# PMUD register map
Vendor: Texas Instruments
Peripheral module from a debugger description file (folder CC23x0R2).
Registers are 32-bit, access per field, reset 0x0 unless marked. A register's access mark holds for its fields unless they carry their own. Offsets are as the file gives them; lines under a group give offsets from that group; [hi:lo] are bit positions; {n}, {i} and the like mark numbered series; 'fields as' and 'values as' point back to an identical list; <NAME> marks a mode.

## PMUD — Digital control signals for VDDR regulator and Battery Monitor
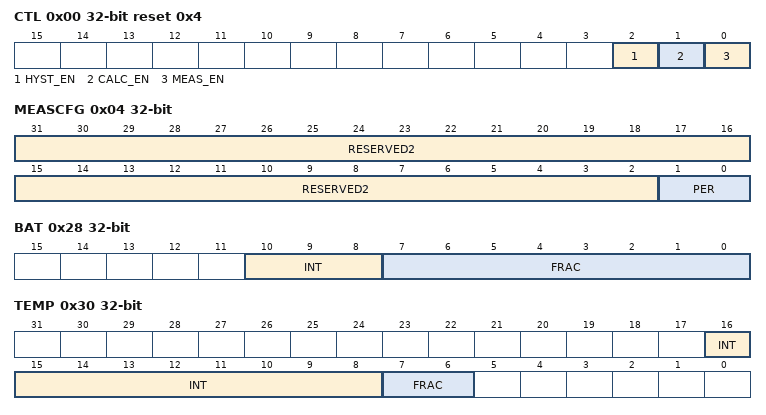
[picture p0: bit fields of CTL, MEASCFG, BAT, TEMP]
0x00 CTL reset 0x4 — Control General Configuration of BATMON
  [2] HYST_EN rw — Enables hysteresis on both battery and temperature measurements.
    1=EN (Enable); 0=DIS (Disable)
  [1] CALC_EN rw — Configuration of the calculation block that converts the digital battery/temperature level to a Volt/Celsius value.
    1=EN (Calculation enabled); 0=DIS (Calculation disabled)
  [0] MEAS_EN rw — Configuration of the measurement block that interfaces with the analog domain.
    1=EN (Measurements enabled (battery voltage and temperature)); 0=DIS (Measurements disabled)
0x04 MEASCFG — Internal. Only to be used through TI provided API.
  [31:2] RESERVED2 ro — Internal. Only to be used through TI provided API.
  [1:0] PER rw — Internal. Only to be used through TI provided API.
    3=_32CYC (Internal. Only to be used through TI provided API.); 2=_16CYC (Internal. Only to be used through TI provided API.); 1=_8CYC (Internal. Only to be used through TI provided API.); 0=CONT (Internal. Only to be used through TI provided API.)
0x28 BAT ro — Last Measured Battery Voltage This register should be read when BATUPD.STA = 1
  [10:8] INT — Integer part: 0x0: Battery voltage = 0V + fractional part ... 0x3: Battery voltage = 3V + fractional part 0x4: Battery voltage = 4V + fractional part
  [7:0] FRAC — Fractional part, standard binary fractional encoding. 0x00: .0V ... 0x20: 1/8 = .125V 0x40: 1/4 = .25V 0x80: 1/2 = .5V ... 0xA0: 1/2 + 1/8 = .625V ... 0xFF: 1/2 + 1/4 + 1/8 + ... + 1/256 = 0.99V
0x2C BATUPD — Battery Update Indicates BAT Updates
  [0] STA rw — Battery update status. Write 1 to clear the status.
    1=UPD (New battery voltage present); 0=NOUPD (No update since last clear)
0x30 TEMP ro — Last measured Temperature in Degree Celsius This register should be read when TEMPUPD.STA = 1.
  [16:8] INT — Integer part of temperature value (signed) Total value = INT + FRAC 2's complement encoding 0x100: Min value (-256°C) 0x1D8: -40°C 0x1FF: -1°C 0x00: 0°C 0x1B: 27°C 0x55: 85°C 0xFF: Max value (255°C)
  [7:6] FRAC — Fractional part of temperature value. Total value = INT + FRAC The encoding is an extension of the 2's complement encoding. 00: 0.0°C 01: 0.25°C 10: 0.5°C 11: 0.75°C For example: 000000001,00 = ( 1+0,00) = 1,00 000000000,11 = ( 0+0,75) = 0,75 000000000,10 = ( 0+0,50) = 0,50 000000000,01 = ( 0+0,25) = 0,25 000000000,00 = ( 0+0,00) = 0,00 111111111,11 = (-1+0,75) = -0,25 111111111,10 = (-1+0,50) = -0,50 111111111,01 = (-1+0,25) = -0,75 111111111,00 = (-1+0,00) = -1,00 111111110,11 = (-2+0,75) = -1,25
0x34 TEMPUPD — Temperature Update Indicates TEMP Updates
  [0] STA rw — Temperature update status. Write 1 to clear the status.
    1=UPD (New temperature value present); 0=NOUPD (No temperature update since last clear)
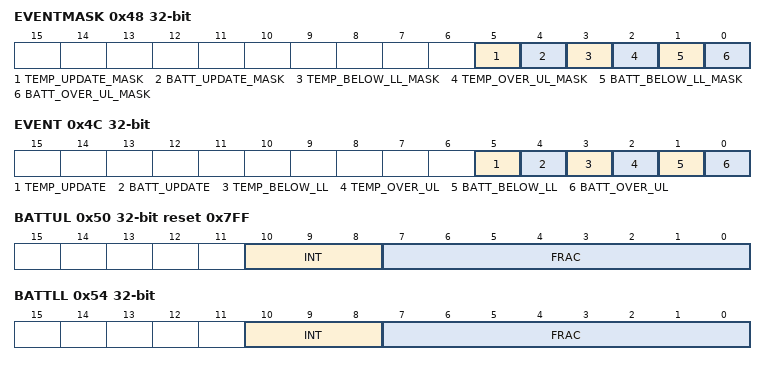
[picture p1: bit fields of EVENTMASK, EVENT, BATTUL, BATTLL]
0x48 EVENTMASK
  [5] TEMP_UPDATE_MASK rw — 1: EVENT.TEMP_UPDATE contributes to combined event from BATMON 0: EVENT.TEMP_UPDATE does not contribute to combined event from BATMON
  [4] BATT_UPDATE_MASK rw — 1: EVENT.BATT_UPDATE contributes to combined event from BATMON 0: EVENT.BATT_UPDATE does not contribute to combined event from BATMON
  [3] TEMP_BELOW_LL_MASK rw — 1: EVENT.TEMP_BELOW_LL contributes to combined event from BATMON 0: EVENT.TEMP_BELOW_LL does not contribute to combined event from BATMON
  [2] TEMP_OVER_UL_MASK rw — 1: EVENT.TEMP_OVER_UL contributes to combined event from BATMON 0: EVENT.TEMP_OVER_UL does not contribute to combined event from BATMON
  [1] BATT_BELOW_LL_MASK rw — 1: EVENT.BATT_BELOW_LL contributes to combined event from BATMON 0: EVENT.BATT_BELOW_LL does not contribute to combined event from BATMON
  [0] BATT_OVER_UL_MASK rw — 1: EVENT.BATT_OVER_UL contributes to combined event from BATMON 0: EVENT.BATT_OVER_UL does not contribute to combined event from BATMON
0x4C EVENT
  [5] TEMP_UPDATE rw — Alias to TEMPUPD.STA
  [4] BATT_UPDATE rw — Alias to BATUPD.STA
  [3] TEMP_BELOW_LL rw — Read: 1: Temperature level is below the lower limit set by TEMPLL. 0: Temperature level is not below the lower limit set by TEMPLL. Write: 1: Clears the flag 0: No change in the flag
  [2] TEMP_OVER_UL rw — Read: 1: Temperature level is above the upper limit set by TEMPUL. 0: Temperature level is not above the upper limit set by TEMPUL. Write: 1: Clears the flag 0: No change in the flag
  [1] BATT_BELOW_LL rw — Read: 1: Battery level is below the lower limit set by BATTLL. 0: Battery level is not below the lower limit set by BATTLL. Write: 1: Clears the flag 0: No change in the flag
  [0] BATT_OVER_UL rw — Read: 1: Battery level is above the upper limit set by BATTUL. 0: Battery level is not above the upper limit set by BATTUL. Write: 1: Clears the flag 0: No change in the flag
0x50 BATTUL reset 0x7FF — Battery Upper Limit Total battery voltage = INT + FRAC It is a sum of integer and fractional parts
  [10:8] INT rw — Integer part: Total battery voltage = INT + FRAC (integer and fractional part) 0x0: Battery voltage = 0V + fractional part ... 0x3: Battery voltage = 3V + fractional part 0x4: Battery voltage = 4V + fractional part
  [7:0] FRAC rw — Fractional part, standard binary fractional encoding. 0x00: .0V ... 0x20: 1/8 = .125V 0x40: 1/4 = .25V 0x80: 1/2 = .5V ... 0xA0: 1/2 + 1/8 = .625V ... 0xFF: 1/2 + 1/4 + 1/8 + ... + 1/256 = 0.99V
0x54 BATTLL — Battery Lower Limit Total battery voltage = INT + FRAC It is a sum of integer and fractional parts
  fields as BATTUL
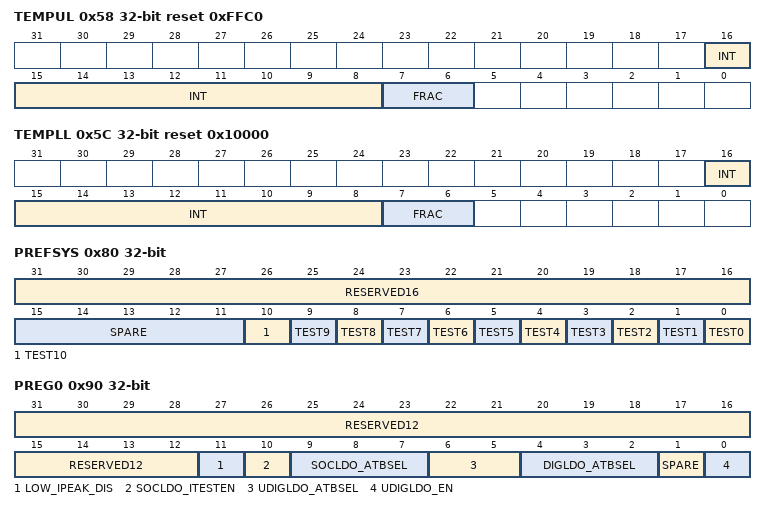
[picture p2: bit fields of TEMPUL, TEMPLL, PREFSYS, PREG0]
0x58 TEMPUL reset 0xFFC0 — Temperature Upper Limit
  [16:8] INT rw — Integer part (signed) of temperature upper limit. Total value = INT + FRAC 2's complement encoding 0x100: Min value (-256°C) 0x1D8: -40°C 0x1FF: -1°C 0x00: 0°C 0x1B: 27°C 0x55: 85°C 0xFF: Max value (255°C)
  [7:6] FRAC rw — Fractional part of temperature upper limit. Total value = INT + FRAC The encoding is an extension of the 2's complement encoding. 00: 0.0°C 01: 0.25°C 10: 0.5°C 11: 0.75°C For example: 000000001,00 = ( 1+0,00) = 1,00 000000000,11 = ( 0+0,75) = 0,75 000000000,10 = ( 0+0,50) = 0,50 000000000,01 = ( 0+0,25) = 0,25 000000000,00 = ( 0+0,00) = 0,00 111111111,11 = (-1+0,75) = -0,25 111111111,10 = (-1+0,50) = -0,50 111111111,01 = (-1+0,25) = -0,75 111111111,00 = (-1+0,00) = -1,00 111111110,11 = (-2+0,75) = -1,25
0x5C TEMPLL reset 0x10000 — Temperature Lower Limit
  [16:8] INT rw — Integer part (signed) of temperature lower limit. Total value = INT + FRAC 2's complement encoding 0x100: Min value (-256°C) 0x1D8: -40°C 0x1FF: -1°C 0x00: 0°C 0x1B: 27°C 0x55: 85°C 0xFF: Max value (255°C)
  [7:6] FRAC rw — Fractional part of temperature lower limit. Total value = INT + FRAC The encoding is an extension of the 2's complement encoding. 00: 0.0°C 01: 0.25°C 10: 0.5°C 11: 0.75°C For example: 000000001,00 = ( 1+0,00) = 1,00 000000000,11 = ( 0+0,75) = 0,75 000000000,10 = ( 0+0,50) = 0,50 000000000,01 = ( 0+0,25) = 0,25 000000000,00 = ( 0+0,00) = 0,00 111111111,11 = (-1+0,75) = -0,25 111111111,10 = (-1+0,50) = -0,50 111111111,01 = (-1+0,25) = -0,75 111111111,00 = (-1+0,00) = -1,00 111111110,11 = (-2+0,75) = -1,25
0x80 PREFSYS — Internal. Only to be used through TI provided API.
  [31:16] RESERVED16 ro — Internal. Only to be used through TI provided API.
  [15:11] SPARE rw — Internal. Only to be used through TI provided API.
  [n] TEST{n} rw (n=0..10) — Internal. Only to be used through TI provided API.
    1=SET (Internal. Only to be used through TI provided API.); 0=CLR (Internal. Only to be used through TI provided API.)
0x90 PREG0 — Internal. Only to be used through TI provided API.
  [31:12] RESERVED12 ro — Internal. Only to be used through TI provided API.
  [11] LOW_IPEAK_DIS rw — Internal. Only to be used through TI provided API.
    values as PREFSYS.TEST0
  [10] SOCLDO_ITESTEN rw — Internal. Only to be used through TI provided API.
    1=EN (Internal. Only to be used through TI provided API.); 0=DIS (Internal. Only to be used through TI provided API.)
  [9:7] SOCLDO_ATBSEL rw — Internal. Only to be used through TI provided API.
    4=VDD_AON (Internal. Only to be used through TI provided API.); 2=SOCLDO_VREF_AMP_OUT (Internal. Only to be used through TI provided API.); 1=SOCLDO_ITEST (Internal. Only to be used through TI provided API.); 0=NC (Internal. Only to be used through TI provided API.)
  [6:5] UDIGLDO_ATBSEL rw — Internal. Only to be used through TI provided API.
    {v}=Internal. Only to be used through TI provided API. (v=0..3)
  [4:2] DIGLDO_ATBSEL rw — Internal. Only to be used through TI provided API.
    4=Internal. Only to be used through TI provided API.; 2=Internal. Only to be used through TI provided API.; 1=Internal. Only to be used through TI provided API.; 0=Internal. Only to be used through TI provided API.
  [1] SPARE rw — Internal. Only to be used through TI provided API.
  [0] UDIGLDO_EN rw — Internal. Only to be used through TI provided API.
    values as SOCLDO_ITESTEN
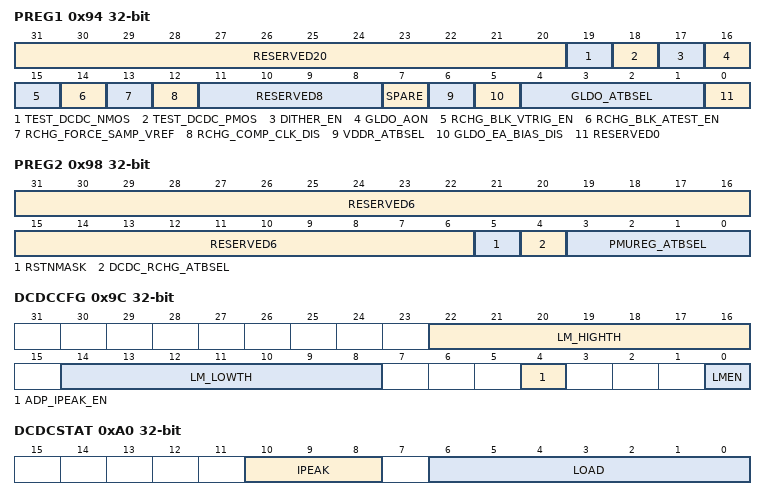
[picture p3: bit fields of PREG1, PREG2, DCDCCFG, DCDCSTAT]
0x94 PREG1 — Internal. Only to be used through TI provided API.
  [31:20] RESERVED20 ro — Internal. Only to be used through TI provided API.
  [19] TEST_DCDC_NMOS rw — Internal. Only to be used through TI provided API.
    values as PREG0.SOCLDO_ITESTEN
  [18] TEST_DCDC_PMOS rw — Internal. Only to be used through TI provided API.
    values as PREG0.SOCLDO_ITESTEN
  [17] DITHER_EN rw — Internal. Only to be used through TI provided API.
    values as PREG0.SOCLDO_ITESTEN
  [16] GLDO_AON rw — Internal. Only to be used through TI provided API.
    values as PREG0.SOCLDO_ITESTEN
  [15] RCHG_BLK_VTRIG_EN rw — Internal. Only to be used through TI provided API.
    values as PREG0.SOCLDO_ITESTEN
  [14] RCHG_BLK_ATEST_EN rw — Internal. Only to be used through TI provided API.
    values as PREG0.SOCLDO_ITESTEN
  [13] RCHG_FORCE_SAMP_VREF rw — Internal. Only to be used through TI provided API.
    values as PREG0.SOCLDO_ITESTEN
  [12] RCHG_COMP_CLK_DIS rw — Internal. Only to be used through TI provided API.
    1=DIS (Internal. Only to be used through TI provided API.); 0=EN (Internal. Only to be used through TI provided API.)
  [11:8] RESERVED8 ro — Internal. Only to be used through TI provided API.
  [7] SPARE rw — Internal. Only to be used through TI provided API.
  [6] VDDR_ATBSEL rw — Internal. Only to be used through TI provided API.
    values as PREG0.SOCLDO_ITESTEN
  [5] GLDO_EA_BIAS_DIS rw — Internal. Only to be used through TI provided API.
    1=OFF (Internal. Only to be used through TI provided API.); 0=ON (Internal. Only to be used through TI provided API.)
  [4:1] GLDO_ATBSEL rw — Internal. Only to be used through TI provided API.
    8=VDDROK (Internal. Only to be used through TI provided API.); 4=IB1U (Internal. Only to be used through TI provided API.); 2=PASSGATE (Internal. Only to be used through TI provided API.); 1=ERRAMP_OUT (Internal. Only to be used through TI provided API.); 0=NC (Internal. Only to be used through TI provided API.)
  [0] RESERVED0 ro — Internal. Only to be used through TI provided API.
0x98 PREG2 — Internal. Only to be used through TI provided API.
  [31:6] RESERVED6 ro — Internal. Only to be used through TI provided API.
  [5] RSTNMASK rw — Internal. Only to be used through TI provided API.
    1=BM (Internal. Only to be used through TI provided API.); 0=BNM (Internal. Only to be used through TI provided API.)
  [4] DCDC_RCHG_ATBSEL rw — Internal. Only to be used through TI provided API.
    1=RCHG_BLK (Internal. Only to be used through TI provided API.); 0=DCDC_GLDO (Internal. Only to be used through TI provided API.)
  [3:0] PMUREG_ATBSEL rw — Internal. Only to be used through TI provided API.
    8=DCDC_ATEST0_RCHG_ATEST1 (Internal. Only to be used through TI provided API.); 4=SOCLDOI_A0 (Internal. Only to be used through TI provided API.); 2=RESERVED (Internal. Only to be used through TI provided API.); 1=SOCLDOV_A1 (Internal. Only to be used through TI provided API.); 0=NC (Internal. Only to be used through TI provided API.)
0x9C DCDCCFG — DCDC configuration register
  [22:16] LM_HIGHTH rw — DCDC load meter high threshold value for adaptive IPEAK adjustment. DCDC load meter output is in percentage scale so the applicable values are 'd1 to 'd100. Values from 'd101 to 'd127 are invalid and not to be used.
  [14:8] LM_LOWTH rw — DCDC load meter low threshold value for adaptive IPEAK adjustment. DCDC load meter output is in percentage scale so the applicable values are 'd1 to 'd100. Values from 'd101 to 'd127 are invalid and not to be used.
  [4] ADP_IPEAK_EN rw — This bit is used to enable adaptive IPEAK adjustment scheme in hardware. When this bit is set, DCDC IPEAK value is automatically adjusted to suitable value by sensing the DCDC load meter output for better DCDC operational efficiency.
    1=EN (Enable); 0=DIS (Disable)
  [0] LMEN rw — This bit is used to enable DCDC load meter. Software can obtain DCDC load meter value from DCDCSTAT regiser and adjust IPEAK setting in SYS0.TDCDC register accordingly.
    1=EN (Enable); 0=DIS (Disable)
0xA0 DCDCSTAT ro — DCDC status register
  [10:8] IPEAK — DCDC IPEAK value. This value is same as what is programmed in SYS0:TMUTE4.IPEAK when adaptive IPEAK adjustment scheme is not enabled, and it shows current IPEAK value applied by hardware when adaptive IPEAK adjustment scheme is enabled. Note: Software can only support IPEAK = 1
  [6:0] LOAD — This indicates DCDC load meter output value in percentage scale. Applicable range is 'd1 to 'd100.
